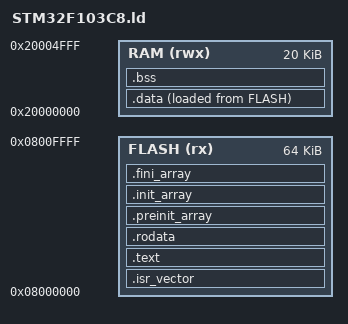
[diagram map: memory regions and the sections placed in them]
/*
 * Linker script for STM32F103C8T6 (HAL 版)
 *
 * Flash: 64K  @ 0x08000000
 * RAM:   20K  @ 0x20000000
 *
 * 比裸机版多了 .init_array / .fini_array 段
 * —— 官方启动文件的 Reset_Handler 会调 __libc_init_array，
 *    需要这两个段存在，否则 HardFault。
 */

ENTRY(Reset_Handler)

MEMORY
{
    FLASH (rx)  : ORIGIN = 0x08000000, LENGTH = 64K
    RAM   (rwx) : ORIGIN = 0x20000000, LENGTH = 20K
}

_estack = ORIGIN(RAM) + LENGTH(RAM);   /* 0x20005000 */

SECTIONS
{
    /* --- .isr_vector: interrupt vector table, must be at flash start --- */
    .isr_vector :
    {
        . = ALIGN(4);
        KEEP(*(.isr_vector))
        . = ALIGN(4);
    } > FLASH

    /* --- .text: executable code --- */
    .text :
    {
        . = ALIGN(4);
        *(.text)
        *(.text*)
        *(.glue_7)
        *(.glue_7t)
        KEEP(*(.init))
        KEEP(*(.fini))
        . = ALIGN(4);
    } > FLASH

    /* --- .rodata: read-only data (const, string literals) --- */
    .rodata :
    {
        . = ALIGN(4);
        *(.rodata)
        *(.rodata*)
        . = ALIGN(4);
    } > FLASH

    /* --- .preinit_array / .init_array / .fini_array --- */
    /* __libc_init_array (called by official startup) walks these tables */
    .preinit_array :
    {
        PROVIDE_HIDDEN(__preinit_array_start = .);
        KEEP(*(.preinit_array*))
        PROVIDE_HIDDEN(__preinit_array_end = .);
    } > FLASH

    .init_array :
    {
        PROVIDE_HIDDEN(__init_array_start = .);
        KEEP(*(SORT(.init_array.*)))
        KEEP(*(.init_array*))
        PROVIDE_HIDDEN(__init_array_end = .);
    } > FLASH

    .fini_array :
    {
        PROVIDE_HIDDEN(__fini_array_start = .);
        KEEP(*(SORT(.fini_array.*)))
        KEEP(*(.fini_array*))
        PROVIDE_HIDDEN(__fini_array_end = .);
    } > FLASH

    /* --- .data: initialized global/static variables --- */
    _sidata = LOADADDR(.data);

    .data :
    {
        . = ALIGN(4);
        _sdata = .;
        *(.data)
        *(.data*)
        . = ALIGN(4);
        _edata = .;
    } > RAM AT> FLASH

    /* --- .bss: uninitialized globals (zeroed by startup code) --- */
    .bss :
    {
        . = ALIGN(4);
        _sbss = .;
        __bss_start__ = _sbss;
        *(.bss)
        *(.bss*)
        *(COMMON)
        . = ALIGN(4);
        _ebss = .;
        __bss_end__ = _ebss;
    } > RAM

    /* --- _end: heap start marker (for malloc if ever needed) --- */
    PROVIDE(end = _ebss);
    PROVIDE(_end = _ebss);
}
